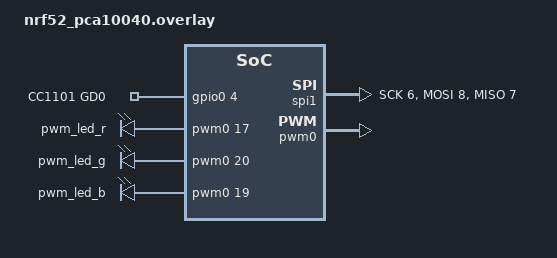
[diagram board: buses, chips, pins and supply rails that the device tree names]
/ {
	buttons {
		gdo0: gdo0 {
			gpios = <&gpio0 4 (GPIO_PULL_DOWN)>;
			label = "CC1101 GD0";
		};
	};

	pwmleds {
		compatible = "pwm-leds";
		pwm_led_r: pwm_led_r {
			pwms = <&pwm0 17>;
		};

		pwm_led_g: pwm_led_g {
			pwms = <&pwm0 20>;
		};

		pwm_led_b: pwm_led_b {
			pwms = <&pwm0 19>;
		};
	};

	aliases {
		cc1101-spi = &spi1;
		cc1101-gdo0 = &gdo0;

		led-r = &pwm_led_r;
		led-g = &pwm_led_g;
		led-b = &pwm_led_b;
	};
};

&spi1 {
	status = "okay";
	sck-pin = <6>;
	mosi-pin = <8>;
	miso-pin = <7>;
	cs-gpios = <&gpio0 5 0>;
};

&pwm0 {
	status = "okay";
	ch0-pin = <17>;
	ch0-inverted;
	ch1-pin = <20>;
	ch1-inverted;
	ch2-pin = <19>;
	ch2-inverted;
};
